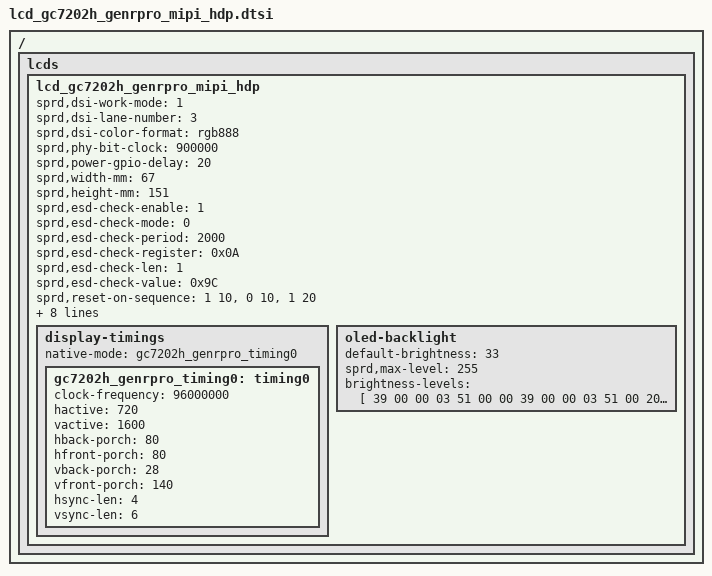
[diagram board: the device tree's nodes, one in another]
/*
 * gc7202h  LCD config dtsi file for spreadtrum
 *
 * Copyright (C) 2018, Spreadtrum Communications Inc.
 *
 * SPDX-License-Identifier: (GPL-2.0+ OR MIT)
 */

/ {
	fragment {
		target-path = "/";
		__overlay__ {
			lcds {
				lcd_gc7202h_genrpro_mipi_hdp: lcd_gc7202h_genrpro_mipi_hdp {
					sprd,dsi-work-mode = <1>; /* video burst mode*/
					sprd,dsi-lane-number = <3>;
					sprd,dsi-color-format = "rgb888";

					sprd,phy-bit-clock = <900000>; /* kbps */
					//sprd,phy-escape-clock = <20000>;/* kHz */
					//sprd,dpi-clk-div = <1>;
					sprd,power-gpio-delay = <20>;/* ms */

					sprd,width-mm = <67>;
					sprd,height-mm = <151>;

					sprd,esd-check-enable = <1>;
					sprd,esd-check-mode = <0>;
					sprd,esd-check-period = <2000>;
					sprd,esd-check-register = <0x0A>;
					sprd,esd-check-len = <1>;
					sprd,esd-check-value = <0x9C>;

					sprd,reset-on-sequence = <1 10>, <0 10>, <1 20>;
					sprd,reset-off-sequence = <0 5>;

					sprd,use-dcs-write;
					sprd,initial-command = [
			39 00 00 04 FF 55 AA 66
			39 00 00 02 FF 26
			39 00 00 02 FB 00
			39 00 00 02 FF B3
			39 00 00 02 FB 00

			39 00 00 02 FF A3
			39 00 00 02 FA 01

			39 00 00 02 FF 27
			39 00 00 11 01 A0 20 00 10 32 54 76 98 BA 00 20 A0 10 01 00 00
			39 00 00 11 02 00 01 02 03 04 05 06 07 08 09 0A 0B 00 00 00 00
			39 00 00 11 03 00 00 88 04 00 00 00 00 00 00 00 00 00 00 00 00
			39 00 00 11 04 50 45 00 00 00 00 00 00 00 00 00 00 00 00 00 00
			39 00 00 11 06 40 00 00 00 00 00 00 00 00 00 00 00 00 00 00 00
			39 00 00 11 07 00 00 00 00 00 00 00 00 00 00 00 00 00 00 00 00
			39 00 00 11 08 25 46 02 02 00 02 00 00 00 00 00 81 FF FF 03 00
			39 00 00 11 09 00 00 00 00 00 00 00 00 00 00 00 00 00 00 00 00
			39 00 00 11 0A 00 00 00 00 00 00 00 00 00 00 00 00 00 00 00 00
			39 00 00 11 0B 00 00 95 00 05 00 00 00 00 00 00 00 00 00 00 00
			39 00 00 11 0C 00 00 00 00 00 00 00 00 00 03 FF 00 00 00 00 00
			39 00 00 11 0D 00 64 83 80 32 13 00 0C 00 00 00 00 00 00 00 00
			39 00 00 11 0E 00 00 00 00 00 00 00 00 00 00 00 00 00 00 00 00
			39 00 00 11 0F 00 00 00 00 00 00 00 00 00 00 00 00 00 00 00 00
			39 00 00 11 10 FF 00 FF 00 FF 00 FF 00 F0 0F 00 00 00 00 00 00
			39 00 00 11 11 55 10 10 0B 0B 14 14 2B 2B 44 1E 1E 00 02 00 00
			39 00 00 11 12 00 03 10 03 10 00 53 00 00 08 08 08 08 00 00 00
			39 00 00 11 13 00 00 00 00 00 00 00 00 00 00 00 00 00 00 00 00
			39 00 00 11 14 14 3A 13 09 14 5F 0F 09 5F 5F 00 00 5F 14 0F 09
			39 00 00 11 15 00 00 00 00 00 00 40 40 00 03 01 33 00 00 00 00
			39 00 00 11 16 41 24 40 44 44 45 21 25 15 00 00 00 00 00 00 00
			39 00 00 11 17 00 00 00 00 01 1A 00 00 00 00 00 00 00 00 00 00
			39 00 00 11 18 00 00 00 00 00 00 00 00 00 00 00 00 00 00 00 00
			39 00 00 11 40 00 00 00 00 03 B2 48 05 00 00 00 00 03 B2 48 05
			39 00 00 11 41 00 00 00 00 03 B2 48 05 00 00 00 00 03 B2 48 05
			39 00 00 11 42 00 00 00 00 03 B2 48 05 00 00 00 00 03 B2 48 05
			39 00 00 11 43 00 00 00 00 03 B2 48 05 00 00 00 00 03 B2 48 05
			39 00 00 11 44 00 00 00 00 03 B2 48 05 00 00 00 00 03 B2 48 05
			39 00 00 11 45 00 00 00 00 00 00 00 00 00 00 00 00 00 00 00 00
			39 00 00 11 46 5D 03 5A 4E 5D 03 5A 4E 5D 03 5A 4E 5D 03 5A 4E
			39 00 00 11 47 5D 05 59 4E 5D 03 5A 4E 5D 05 59 4E 5D 01 5B 4E
			39 00 00 11 48 5B 3F 3C 4E 31 40 55 55 63 40 55 55 95 40 55 55
			39 00 00 11 49 DB 45 55 55 00 00 00 00 00 00 00 00 C7 00 00 00
			39 00 00 11 4A 59 00 00 00 95 40 71 06 C9 00 59 00 95 40 71 06
			39 00 00 11 4B C9 00 59 00 95 40 71 06 C9 00 59 00 26 C6 08 00
			39 00 00 11 4C D1 06 E8 8A 97 02 5A 4E 97 02 5A 4E 97 02 5A 4E
			39 00 00 11 4D 97 02 5A 4E 97 04 59 4E 97 02 5A 4E 97 04 59 4E
			39 00 00 11 4E 97 00 5B 4E 95 3E 3C 4E 00 00 00 00 00 00 00 00
			39 00 00 11 4F 31 40 00 00 77 45 00 00 00 00 00 00 00 00 00 00
			39 00 00 11 50 C7 00 00 00 59 00 00 00 01 00 A9 05 C9 00 59 00
			39 00 00 11 51 01 00 A9 05 C9 00 59 00 01 00 A9 05 C9 00 59 00
			39 00 00 11 52 26 C6 48 00 11 02 B8 04 97 02 5A 4E 97 02 5A 4E
			39 00 00 11 53 97 02 5A 4E 97 02 5A 4E 97 04 59 4E 97 02 5A 4E
			39 00 00 11 54 97 04 59 4E 97 00 5B 4E 95 3E 3C 4E 00 00 00 00
			39 00 00 11 55 00 00 00 00 31 00 01 00 77 05 01 00 00 00 00 00
			39 00 00 11 56 00 00 00 00 C7 00 00 00 59 00 00 00 01 00 A9 05
			39 00 00 11 57 C9 00 59 00 01 00 A9 05 C9 00 59 00 01 00 A9 05
			39 00 00 11 58 C9 00 59 00 26 C6 88 00 11 02 B8 04 97 02 5A 4E
			39 00 00 11 59 97 02 5A 4E 97 02 5A 4E 97 02 5A 4E 97 04 59 4E
			39 00 00 11 5A 97 02 5A 4E 97 04 59 4E 97 00 5B 4E 95 3E 3C 4E
			39 00 00 11 5B 00 00 00 00 00 00 00 00 31 00 04 00 77 05 04 00
			39 00 00 11 5C 00 00 00 00 00 00 00 00 C7 00 00 00 59 00 00 00
			39 00 00 11 5D 01 00 A9 05 C9 00 59 00 01 00 A9 05 C9 00 59 00
			39 00 00 11 5E 01 00 A9 05 C9 00 59 00 26 C6 C8 00 11 02 B8 04
			39 00 00 11 5F 97 02 5A 4E 97 02 5A 4E 97 02 5A 4E 97 02 5A 4E
			39 00 00 11 60 97 04 59 4E 97 02 5A 4E 97 04 59 4E 97 00 5B 4E
			39 00 00 11 61 95 3E 3C 4E 00 00 00 00 00 00 00 00 31 00 10 00
			39 00 00 11 62 77 05 10 00 00 00 00 00 00 00 00 00 C7 00 00 00
			39 00 00 11 63 59 00 00 00 01 00 A9 05 C9 00 59 00 01 00 A9 05
			39 00 00 11 64 C9 00 59 00 01 00 A9 05 C9 00 59 00 26 C6 08 01
			39 00 00 11 65 11 02 B8 04 97 02 5A 4E 97 02 5A 4E 97 02 5A 4E
			39 00 00 11 66 97 02 5A 4E 97 04 59 4E 97 02 5A 4E 97 04 59 4E
			39 00 00 11 67 97 00 5B 4E 95 3E 3C 4E 00 00 00 00 00 00 00 00
			39 00 00 11 68 31 00 40 00 77 05 40 00 00 00 00 00 00 00 00 00
			39 00 00 11 69 C7 00 00 00 59 00 00 00 01 00 A9 05 C9 00 59 00
			39 00 00 11 6A 01 00 A9 05 C9 00 59 00 01 00 A9 05 C9 00 59 00
			39 00 00 11 6B 26 C6 48 01 11 02 B8 04 97 02 5A 4E 97 02 5A 4E
			39 00 00 11 6C 97 02 5A 4E 97 02 5A 4E 97 04 59 4E 97 02 5A 4E
			39 00 00 11 6D 97 04 59 4E 97 00 5B 4E 95 3E 3C 4E 00 00 00 00
			39 00 00 11 6E 00 00 00 00 31 00 00 01 77 05 00 01 00 00 00 00
			39 00 00 11 6F 00 00 00 00 C7 00 00 00 59 00 00 00 01 00 A9 05
			39 00 00 11 70 C9 00 59 00 01 00 A9 05 C9 00 59 00 01 00 A9 05
			39 00 00 11 71 C9 00 59 00 26 C6 88 01 11 02 B8 04 97 02 5A 4E
			39 00 00 11 72 97 02 5A 4E 97 02 5A 4E 97 02 5A 4E 97 04 59 4E
			39 00 00 11 73 97 02 5A 4E 97 04 59 4E 97 00 5B 4E 95 3E 3C 4E
			39 00 00 11 74 00 00 00 00 00 00 00 00 31 00 00 04 77 05 00 04
			39 00 00 11 75 00 00 00 00 00 00 00 00 C7 00 00 00 59 00 00 00
			39 00 00 11 76 01 00 A9 05 C9 00 59 00 01 00 A9 05 C9 00 59 00
			39 00 00 11 77 01 00 A9 05 C9 00 59 00 26 C6 C8 01 11 02 B8 04
			39 00 00 11 78 97 02 5A 4E 97 02 5A 4E 97 02 5A 4E 97 02 5A 4E
			39 00 00 11 79 97 04 59 4E 97 02 5A 4E 97 04 59 4E 97 00 5B 4E
			39 00 00 11 7A 95 3E 3C 4E 00 00 00 00 00 00 00 00 31 00 00 10
			39 00 00 11 7B 77 05 00 10 00 00 00 00 00 00 00 00 C7 00 00 00
			39 00 00 11 7C 59 00 00 00 01 00 A9 05 C9 00 59 00 01 00 A9 05
			39 00 00 11 7D C9 00 59 00 01 00 A9 05 C9 00 59 00 26 C6 08 02
			39 00 00 11 7E 11 02 B8 04 97 02 5A 4E 97 02 5A 4E 97 02 5A 4E
			39 00 00 11 7F 97 02 5A 4E 97 04 59 4E 97 02 5A 4E 97 04 59 4E
			39 00 00 11 80 97 00 5B 4E 95 3E 3C 4E 00 00 00 00 00 00 00 00
			39 00 00 11 81 31 00 00 40 77 05 00 40 C7 C0 FF FF 63 C0 FF FF
			39 00 00 11 82 31 00 00 00 00 00 00 00 01 00 71 46 95 00 00 00
			39 00 00 11 83 01 00 71 46 95 00 00 00 01 00 71 46 95 00 00 20
			39 00 00 11 84 26 C6 48 02 11 02 B8 14 00 00 00 00 00 00 00 00
			39 00 00 11 85 00 00 00 00 00 00 00 00 00 00 00 00 00 00 00 00
			39 00 00 11 86 00 00 00 00 00 00 00 00 00 00 00 00 00 00 00 00
			39 00 00 11 87 00 00 00 00 00 00 00 00 00 00 00 00 00 00 00 00
			39 00 00 11 88 00 00 00 00 00 00 00 00 00 00 00 00 00 00 00 00
			39 00 00 11 89 00 00 00 00 00 00 00 00 00 00 00 00 00 00 00 00
			39 00 00 11 8A 00 00 00 00 00 00 00 00 00 00 00 00 00 00 00 00
			39 00 00 11 8B 00 00 00 00 00 00 00 00 00 00 00 00 00 00 00 00
			39 00 00 11 8C 00 00 00 00 00 00 00 00 00 00 00 00 00 00 00 00
			39 00 00 11 8D 00 00 00 00 00 00 00 00 00 00 00 00 00 00 00 00
			39 00 00 11 8E 00 00 00 00 00 00 00 00 00 00 00 00 00 00 00 00
			39 00 00 11 8F 00 00 00 00 00 00 00 00 00 00 00 00 00 00 00 00
			39 00 00 11 90 00 00 00 00 00 00 00 00 00 00 40 00 00 00 00 00
			39 00 00 11 91 01 00 00 00 01 00 00 00 01 00 00 00 01 00 00 00
			39 00 00 11 92 01 00 00 00 01 00 00 00 01 00 00 00 01 00 00 00
			39 00 00 11 93 01 00 00 00 01 25 00 00 00 00 00 00 00 00 00 00

			39 00 00 02 FF 22
			39 00 00 02 E4 01
			39 00 00 02 01 06
			39 00 00 02 02 40
			39 00 00 02 25 08
			39 00 00 02 26 00
			39 00 00 02 2E 6F
			39 00 00 02 2F 00
			39 00 00 02 36 09
			39 00 00 02 37 00
			39 00 00 02 3F 6F
			39 00 00 02 40 00

			39 00 00 02 FF 28
			39 00 00 02 01 25
			39 00 00 02 02 05
			39 00 00 02 03 1A
			39 00 00 02 04 25
			39 00 00 02 05 25
			39 00 00 02 06 01
			39 00 00 02 07 0F
			39 00 00 02 08 0D
			39 00 00 02 09 0B
			39 00 00 02 0A 09
			39 00 00 02 0B 23
			39 00 00 02 0C 23
			39 00 00 02 0D 25
			39 00 00 02 0E 25
			39 00 00 02 0F 25
			39 00 00 02 10 25
			39 00 00 02 11 25
			39 00 00 02 12 25
			39 00 00 02 13 25
			39 00 00 02 14 25
			39 00 00 02 15 25
			39 00 00 02 16 25
			39 00 00 02 17 25
			39 00 00 02 18 04
			39 00 00 02 19 1A
			39 00 00 02 1A 25
			39 00 00 02 1B 25
			39 00 00 02 1C 00
			39 00 00 02 1D 0E
			39 00 00 02 1E 0C
			39 00 00 02 1F 0A
			39 00 00 02 20 08
			39 00 00 02 21 23
			39 00 00 02 22 23
			39 00 00 02 23 25
			39 00 00 02 24 25
			39 00 00 02 25 25
			39 00 00 02 26 25
			39 00 00 02 27 25
			39 00 00 02 28 25
			39 00 00 02 29 25
			39 00 00 02 2A 25
			39 00 00 02 2B 25

			39 00 00 02 FF 21
			39 00 00 02 2E 00
			39 00 00 02 88 A7
			39 00 00 02 89 28
			39 00 00 02 8A 33
			39 00 00 02 94 A7
			39 00 00 02 95 28
			39 00 00 02 96 33
			39 00 00 02 45 73
			39 00 00 02 46 53
			39 00 00 02 47 02
			39 00 00 02 48 01
			39 00 00 02 4C 53
			39 00 00 02 4D 01
			39 00 00 02 4E 02
			39 00 00 02 5E 41
			39 00 00 02 5F 21
			39 00 00 02 60 22
			39 00 00 02 64 41
			39 00 00 02 65 22
			39 00 00 02 66 21
			39 00 00 02 7B 04
			39 00 00 02 7C 04
			39 00 00 02 7D 04
			39 00 00 02 7E 03
			39 00 00 02 7F 21
			39 00 00 02 80 01
			39 00 00 02 81 1A
			39 00 00 02 82 50
			39 00 00 02 83 04
			39 00 00 02 87 00
			39 00 00 02 8B 21
			39 00 00 02 8C 1A
			39 00 00 02 8D 01
			39 00 00 02 8E 50
			39 00 00 02 8F 04
			39 00 00 02 93 00
			39 00 00 02 76 40
			39 00 00 02 77 40
			39 00 00 02 7A 44
			39 00 00 02 7B 44
			39 00 00 02 AF 40
			39 00 00 02 B0 40
			39 00 00 02 C2 84
			39 00 00 02 C6 16
			39 00 00 02 2B 00
			39 00 00 02 49 32
			39 00 00 02 4A 32
			39 00 00 02 4F 32
			39 00 00 02 50 32
			39 00 00 02 61 32
			39 00 00 02 62 32
			39 00 00 02 67 32
			39 00 00 02 68 32
			39 00 00 02 6D 32
			39 00 00 02 6E 32
			39 00 00 02 84 32
			39 00 00 02 85 32
			39 00 00 02 90 32
			39 00 00 02 91 32
			39 00 00 02 30 00
			39 00 00 02 31 00
			39 00 00 02 DC 27
			39 00 00 02 E0 80
			39 00 00 02 E1 27
			39 00 00 02 E2 80
			39 00 00 02 FF 20
			39 00 00 02 2D 1F

			39 00 00 02 FF B3
			39 00 00 02 4A 00
			39 00 00 02 7D 28
			39 00 00 02 5B 00
			39 00 00 02 48 23
			39 00 00 02 7C 88
			39 00 00 02 79 20
			39 00 00 02 FF 22
			39 00 00 02 0E 33

			39 00 00 02 FF 28
			39 00 00 02 2F 13
			39 00 00 02 6A 01
			39 00 00 02 3D 37
			39 00 00 02 3E 37
			39 00 00 02 3F 4f
			39 00 00 02 40 4f
			39 00 00 02 45 31
			39 00 00 02 46 31
			39 00 00 02 47 4c
			39 00 00 02 48 4c
			39 00 00 02 5A 78
			39 00 00 02 5B 84



			39 00 00 02 FF 20
			39 00 00 02 A5 00
			39 00 00 02 A6 FF
			39 00 00 02 A9 00
			39 00 00 02 AA FF
			39 00 00 02 AD 00
			39 00 00 02 AE FF
			39 00 00 02 B1 00
			39 00 00 02 B2 FF
			39 00 00 02 C3 00
			39 00 00 02 C4 5F
			39 00 00 02 C5 00
			39 00 00 02 C6 5F
			39 00 00 02 B3 00
			39 00 00 02 B4 20
			39 00 00 02 B5 00
			39 00 00 02 B6 DC
			39 00 00 02 C7 00
			39 00 00 02 C8 93
			39 00 00 02 C9 00
			39 00 00 02 CA 93
			39 00 00 02 B7 00
			39 00 00 02 B8 20
			39 00 00 02 B9 01
			39 00 00 02 BA 90
			39 00 00 02 CB 00
			39 00 00 02 CC 90
			39 00 00 02 BB 00
			39 00 00 02 BC 16
			39 00 00 02 BD 00
			39 00 00 02 BE 12
			39 00 00 02 D5 0E

			39 00 00 02 7E 00
			39 00 00 02 7F 00
			39 00 00 02 80 01
			39 00 00 02 81 00
			39 00 00 02 82 64
			39 00 00 02 83 64
			39 00 00 02 84 64
			39 00 00 02 85 3F
			39 00 00 02 86 76
			39 00 00 02 87 3F
			39 00 00 02 88 76
			39 00 00 02 8A 0A
			39 00 00 02 8B 0A
			39 00 00 02 FF 28
			39 00 00 02 53 66
			39 00 00 02 50 6E
			39 00 00 02 52 5A
			39 00 00 02 FF 20
			39 00 00 02 A3 45
			39 00 00 02 A7 45
			39 00 00 02 4D 00
			39 00 00 02 D3 06
			39 00 00 02 24 99

			39 00 00 02 FF 23
			39 00 00 11 01 00 0A 00 1D 00 32 00 46 00 5A 00 70 00 79 00 8C
			39 00 00 11 02 00 93 00 BE 00 E1 01 1C 01 4B 01 94 01 D0 01 D1
			39 00 00 11 03 02 15 02 62 02 90 02 c9 02 F0 03 2A 03 44 03 53
			39 00 00 0D 04 03 63 03 74 03 86 03 9A 03 AF 03 B9
			39 00 00 11 05 00 0A 00 1D 00 32 00 46 00 5A 00 70 00 79 00 8C
			39 00 00 11 06 00 93 00 BE 00 E1 01 1C 01 4B 01 94 01 D0 01 D1
			39 00 00 11 07 02 15 02 62 02 90 02 c9 02 F0 03 2A 03 44 03 53
			39 00 00 0D 08 03 63 03 74 03 86 03 9A 03 AF 03 B9
			39 00 00 11 09 00 0A 00 1D 00 32 00 46 00 5A 00 70 00 79 00 8C
			39 00 00 11 0A 00 93 00 BE 00 E1 01 1C 01 4B 01 94 01 D0 01 D1
			39 00 00 11 0B 02 15 02 62 02 90 02 c9 02 F0 03 2A 03 44 03 53
			39 00 00 0D 0C 03 63 03 74 03 86 03 9A 03 AF 03 B9
			39 00 00 11 0D 00 0A 00 1D 00 32 00 46 00 5A 00 70 00 79 00 8C
			39 00 00 11 0E 00 93 00 BE 00 E1 01 1C 01 4B 01 94 01 D0 01 D1
			39 00 00 11 0F 02 15 02 62 02 90 02 c9 02 F0 03 2A 03 44 03 53
			39 00 00 0D 10 03 63 03 74 03 86 03 9A 03 AF 03 B9
			39 00 00 11 11 00 0A 00 1D 00 32 00 46 00 5A 00 70 00 79 00 8C
			39 00 00 11 12 00 93 00 BE 00 E1 01 1C 01 4B 01 94 01 D0 01 D1
			39 00 00 11 13 02 15 02 62 02 90 02 c9 02 F0 03 2A 03 44 03 53
			39 00 00 0D 14 03 63 03 74 03 86 03 9A 03 AF 03 B9
			39 00 00 11 15 00 0A 00 1D 00 32 00 46 00 5A 00 70 00 79 00 8C
			39 00 00 11 16 00 93 00 BE 00 E1 01 1C 01 4B 01 94 01 D0 01 D1
			39 00 00 11 17 02 15 02 62 02 90 02 c9 02 F0 03 2A 03 44 03 53
			39 00 00 0D 18 03 63 03 74 03 86 03 9A 03 AF 03 B9
			39 00 00 02 2E 00


			39 00 00 02 FF B3
			39 00 00 02 51 11
			39 00 00 02 3F 3B
			39 00 00 02 82 1A
			39 00 00 02 53 1A
			39 00 00 02 FF 26
			39 00 00 04 1D 0C 00 00
			39 00 00 02 FF B3
			39 00 00 02 3E 03
			39 00 00 02 FF 20
			39 00 00 02 25 16
			39 00 00 02 FF 10
			39 00 00 02 36 08
			39 00 00 02 69 00
			39 00 00 02 35 00
			39 00 00 02 BA 02

			39 00 00 02 35 00
			39 00 00 03 51 00 00
			39 00 00 02 53 2C

			39 80 00 01 11
			39 C8 00 01 29
						];

					sprd,sleep-in-command = [
						39 20 00 01 28
						39 80 00 01 10
						];

					sprd,sleep-out-command = [
						39 78 00 01 11
						39 32 00 01 29
						];

					display-timings {
						native-mode = <&gc7202h_genrpro_timing0>;

						gc7202h_genrpro_timing0: timing0 {
							clock-frequency = <96000000>;
							hactive = <720>;
							vactive = <1600>;
							hback-porch = <80>;
							hfront-porch = <80>;
							vback-porch = <28>;
							vfront-porch = <140>;
							hsync-len = <4>;
							vsync-len = <6>;
						};
					};

					oled-backlight {
						default-brightness = <33>;
						sprd,max-level = <255>;
						brightness-levels = [
							39 00 00 03 51 00 00
							39 00 00 03 51 00 20
							39 00 00 03 51 00 30
							39 00 00 03 51 00 40
							39 00 00 03 51 00 50
							39 00 00 03 51 00 60
							39 00 00 03 51 00 70
							39 00 00 03 51 00 80
							39 00 00 03 51 00 90
							39 00 00 03 51 00 A0
							39 00 00 03 51 00 B0
							39 00 00 03 51 00 C0
							39 00 00 03 51 00 D0
							39 00 00 03 51 00 E0
							39 00 00 03 51 00 F0
							39 00 00 03 51 01 00
							39 00 00 03 51 01 11
							39 00 00 03 51 01 21
							39 00 00 03 51 01 31
							39 00 00 03 51 01 41
							39 00 00 03 51 01 51
							39 00 00 03 51 01 61
							39 00 00 03 51 01 71
							39 00 00 03 51 01 81
							39 00 00 03 51 01 91
							39 00 00 03 51 01 A1
							39 00 00 03 51 01 B1
							39 00 00 03 51 01 C1
							39 00 00 03 51 01 D1
							39 00 00 03 51 01 E1
							39 00 00 03 51 01 F1
							39 00 00 03 51 02 01
							39 00 00 03 51 02 11
							39 00 00 03 51 02 22
							39 00 00 03 51 02 32
							39 00 00 03 51 02 42
							39 00 00 03 51 02 52
							39 00 00 03 51 02 62
							39 00 00 03 51 02 72
							39 00 00 03 51 02 82
							39 00 00 03 51 02 92
							39 00 00 03 51 02 A2
							39 00 00 03 51 02 B2
							39 00 00 03 51 02 C2
							39 00 00 03 51 02 D2
							39 00 00 03 51 02 E2
							39 00 00 03 51 02 F2
							39 00 00 03 51 03 02
							39 00 00 03 51 03 12
							39 00 00 03 51 03 22
							39 00 00 03 51 03 32
							39 00 00 03 51 03 43
							39 00 00 03 51 03 53
							39 00 00 03 51 03 63
							39 00 00 03 51 03 73
							39 00 00 03 51 03 83
							39 00 00 03 51 03 93
							39 00 00 03 51 03 A3
							39 00 00 03 51 03 B3
							39 00 00 03 51 03 C3
							39 00 00 03 51 03 D3
							39 00 00 03 51 03 E3
							39 00 00 03 51 03 F3
							39 00 00 03 51 04 03
							39 00 00 03 51 04 13
							39 00 00 03 51 04 23
							39 00 00 03 51 04 33
							39 00 00 03 51 04 43
							39 00 00 03 51 04 54
							39 00 00 03 51 04 64
							39 00 00 03 51 04 74
							39 00 00 03 51 04 84
							39 00 00 03 51 04 94
							39 00 00 03 51 04 A4
							39 00 00 03 51 04 B4
							39 00 00 03 51 04 C4
							39 00 00 03 51 04 D4
							39 00 00 03 51 04 E4
							39 00 00 03 51 04 F4
							39 00 00 03 51 05 04
							39 00 00 03 51 05 14
							39 00 00 03 51 05 24
							39 00 00 03 51 05 34
							39 00 00 03 51 05 44
							39 00 00 03 51 05 54
							39 00 00 03 51 05 65
							39 00 00 03 51 05 75
							39 00 00 03 51 05 85
							39 00 00 03 51 05 95
							39 00 00 03 51 05 A5
							39 00 00 03 51 05 B5
							39 00 00 03 51 05 C5
							39 00 00 03 51 05 D5
							39 00 00 03 51 05 E5
							39 00 00 03 51 05 F5
							39 00 00 03 51 06 05
							39 00 00 03 51 06 15
							39 00 00 03 51 06 25
							39 00 00 03 51 06 35
							39 00 00 03 51 06 45
							39 00 00 03 51 06 55
							39 00 00 03 51 06 65
							39 00 00 03 51 06 76
							39 00 00 03 51 06 86
							39 00 00 03 51 06 96
							39 00 00 03 51 06 A6
							39 00 00 03 51 06 B6
							39 00 00 03 51 06 C6
							39 00 00 03 51 06 D6
							39 00 00 03 51 06 E6
							39 00 00 03 51 06 F6
							39 00 00 03 51 07 06
							39 00 00 03 51 07 16
							39 00 00 03 51 07 26
							39 00 00 03 51 07 36
							39 00 00 03 51 07 46
							39 00 00 03 51 07 56
							39 00 00 03 51 07 66
							39 00 00 03 51 07 76
							39 00 00 03 51 07 87
							39 00 00 03 51 07 97
							39 00 00 03 51 07 A7
							39 00 00 03 51 07 B7
							39 00 00 03 51 07 C7
							39 00 00 03 51 07 D7
							39 00 00 03 51 07 E7
							39 00 00 03 51 07 F7
							39 00 00 03 51 08 07
							39 00 00 03 51 08 17
							39 00 00 03 51 08 27
							39 00 00 03 51 08 37
							39 00 00 03 51 08 47
							39 00 00 03 51 08 57
							39 00 00 03 51 08 67
							39 00 00 03 51 08 77
							39 00 00 03 51 08 87
							39 00 00 03 51 08 98
							39 00 00 03 51 08 A8
							39 00 00 03 51 08 B8
							39 00 00 03 51 08 C8
							39 00 00 03 51 08 D8
							39 00 00 03 51 08 E8
							39 00 00 03 51 08 F8
							39 00 00 03 51 09 08
							39 00 00 03 51 09 18
							39 00 00 03 51 09 28
							39 00 00 03 51 09 38
							39 00 00 03 51 09 48
							39 00 00 03 51 09 58
							39 00 00 03 51 09 68
							39 00 00 03 51 09 78
							39 00 00 03 51 09 88
							39 00 00 03 51 09 98
							39 00 00 03 51 09 A9
							39 00 00 03 51 09 B9
							39 00 00 03 51 09 C9
							39 00 00 03 51 09 D9
							39 00 00 03 51 09 E9
							39 00 00 03 51 09 F9
							39 00 00 03 51 0A 09
							39 00 00 03 51 0A 19
							39 00 00 03 51 0A 29
							39 00 00 03 51 0A 39
							39 00 00 03 51 0A 49
							39 00 00 03 51 0A 59
							39 00 00 03 51 0A 69
							39 00 00 03 51 0A 79
							39 00 00 03 51 0A 89
							39 00 00 03 51 0A 99
							39 00 00 03 51 0A A9
							39 00 00 03 51 0A BA
							39 00 00 03 51 0A CA
							39 00 00 03 51 0A DA
							39 00 00 03 51 0A EA
							39 00 00 03 51 0A FA
							39 00 00 03 51 0B 0A
							39 00 00 03 51 0B 1A
							39 00 00 03 51 0B 2A
							39 00 00 03 51 0B 3A
							39 00 00 03 51 0B 4A
							39 00 00 03 51 0B 5A
							39 00 00 03 51 0B 6A
							39 00 00 03 51 0B 7A
							39 00 00 03 51 0B 8A
							39 00 00 03 51 0B 9A
							39 00 00 03 51 0B AA
							39 00 00 03 51 0B BA
							39 00 00 03 51 0B CB
							39 00 00 03 51 0B DB
							39 00 00 03 51 0B EB
							39 00 00 03 51 0B FB
							39 00 00 03 51 0C 0B
							39 00 00 03 51 0C 1B
							39 00 00 03 51 0C 2B
							39 00 00 03 51 0C 3B
							39 00 00 03 51 0C 4B
							39 00 00 03 51 0C 5B
							39 00 00 03 51 0C 6B
							39 00 00 03 51 0C 7B
							39 00 00 03 51 0C 8B
							39 00 00 03 51 0C 9B
							39 00 00 03 51 0C AB
							39 00 00 03 51 0C BB
							39 00 00 03 51 0C CB
							39 00 00 03 51 0C DC
							39 00 00 03 51 0C EC
							39 00 00 03 51 0C FC
							39 00 00 03 51 0D 0C
							39 00 00 03 51 0D 1C
							39 00 00 03 51 0D 2C
							39 00 00 03 51 0D 3C
							39 00 00 03 51 0D 4C
							39 00 00 03 51 0D 5C
							39 00 00 03 51 0D 6C
							39 00 00 03 51 0D 7C
							39 00 00 03 51 0D 8C
							39 00 00 03 51 0D 9C
							39 00 00 03 51 0D AC
							39 00 00 03 51 0D BC
							39 00 00 03 51 0D CC
							39 00 00 03 51 0D DC
							39 00 00 03 51 0D ED
							39 00 00 03 51 0D FD
							39 00 00 03 51 0E 0D
							39 00 00 03 51 0E 1D
							39 00 00 03 51 0E 2D
							39 00 00 03 51 0E 3D
							39 00 00 03 51 0E 4D
							39 00 00 03 51 0E 5D
							39 00 00 03 51 0E 6D
							39 00 00 03 51 0E 7D
							39 00 00 03 51 0E 8D
							39 00 00 03 51 0E 9D
							39 00 00 03 51 0E AD
							39 00 00 03 51 0E BD
							39 00 00 03 51 0E CD
							39 00 00 03 51 0E DD
							39 00 00 03 51 0E ED
							39 00 00 03 51 0E FE
							39 00 00 03 51 0F 0E
							39 00 00 03 51 0F 1E
							39 00 00 03 51 0F 2E
							39 00 00 03 51 0F 3E
							39 00 00 03 51 0F 4E
							39 00 00 03 51 0F 5E
							39 00 00 03 51 0F 6E
							39 00 00 03 51 0F 7E
							39 00 00 03 51 0F 8E
							39 00 00 03 51 0F 9E
							39 00 00 03 51 0F AE
							39 00 00 03 51 0F BE
							39 00 00 03 51 0F CE
							39 00 00 03 51 0F DE
							39 00 00 03 51 0F EE
							39 00 00 03 51 0F FE
							39 00 00 03 51 0F FE
						];
					};
				};
			};
		};
	};
};
